AUTOSAR XML (schema 00052)
standard types defined: boolean, float64, sint8, uint16, uint32, uint8, boolean_CompuMethod, float64_DataConstr, sint8_DataConstr, uint16_DataConstr, uint32_DataConstr, uint8_DataConstr
package /ComponentTypes
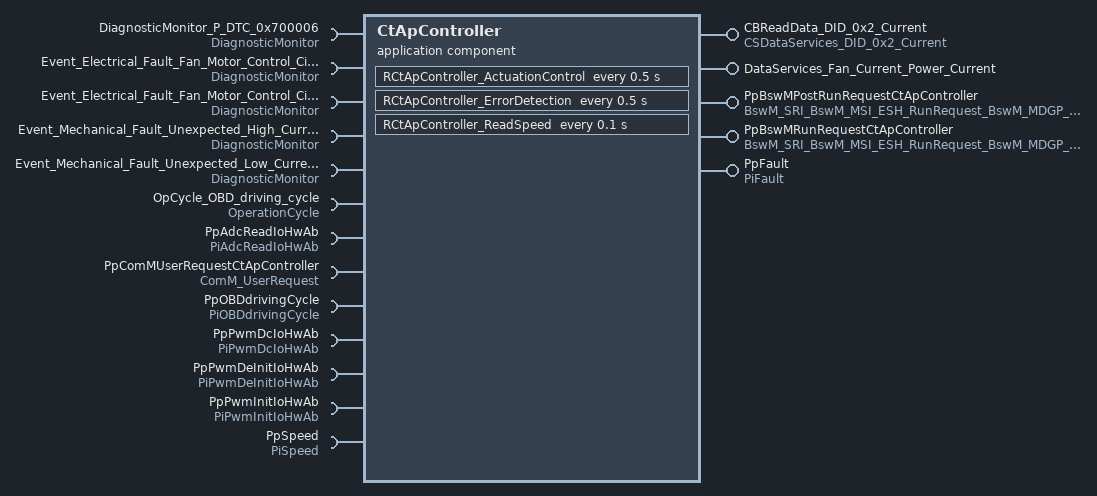
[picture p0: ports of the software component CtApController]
  application sw component type CtApController
    5 x provide port:
      CBReadData_DID_0x2_Current: server-com-spec{operation=CSDataServices_DID_0x2_Current/ReadData, queue-length=1}, provided-interface=CSDataServices_DID_0x2_Current
      DataServices_Fan_Current_Power_Current: provided-interface=DataServices_Fan_Current_Power_Current
        provided-com-specs:
          operation=ConditionCheckRead, queue-length=1
          operation=DataServices_Fan_Current_Power_Current/ReadData, queue-length=1
      PpBswMPostRunRequestCtApController: nonqueued-sender-com-spec=data-element=requestedMode, provided-interface=BswM_SRI_BswM_MSI_ESH_RunRequest_BswM_MDGP_ESH_RunRequest
      PpBswMRunRequestCtApController: nonqueued-sender-com-spec=data-element=requestedMode, provided-interface=BswM_SRI_BswM_MSI_ESH_RunRequest_BswM_MDGP_ESH_RunRequest
      PpFault: nonqueued-sender-com-spec{data-element=DeFault, init-value=0}, provided-interface=PiFault
    13 x require port:
      DiagnosticMonitor_P_DTC_0x700006: required-interface=DiagnosticMonitor
        required-com-specs:
          GetDTCOfEvent
          GetEventExtendedDataRecordEx
          GetEventFailed
          GetEventFreezeFrameDataEx
          GetEventStatus
          GetEventTested
          GetEventUdsStatus
          GetFaultDetectionCounter
          ResetEventDebounceStatus
          ResetEventStatus
          SetEventStatus
      Event_Electrical_Fault_Fan_Motor_Control_Circuit_Open: required-interface=DiagnosticMonitor
        required-com-specs:
          GetDTCOfEvent
          GetEventExtendedDataRecordEx
          GetEventFailed
          GetEventFreezeFrameDataEx
          GetEventStatus
          GetEventTested
          GetEventUdsStatus
          GetFaultDetectionCounter
          ResetEventDebounceStatus
          ResetEventStatus
          SetEventStatus
      Event_Electrical_Fault_Fan_Motor_Control_Circuit_Short: required-interface=DiagnosticMonitor
        required-com-specs:
          GetDTCOfEvent
          GetEventExtendedDataRecordEx
          GetEventFailed
          GetEventFreezeFrameDataEx
          GetEventStatus
          GetEventTested
          GetEventUdsStatus
          GetFaultDetectionCounter
          ResetEventDebounceStatus
          ResetEventStatus
          SetEventStatus
      Event_Mechanical_Fault_Unexpected_High_Current: required-interface=DiagnosticMonitor
        required-com-specs:
          GetDTCOfEvent
          GetEventExtendedDataRecordEx
          GetEventFailed
          GetEventFreezeFrameDataEx
          GetEventStatus
          GetEventTested
          GetEventUdsStatus
          GetFaultDetectionCounter
          ResetEventDebounceStatus
          ResetEventStatus
          SetEventStatus
      Event_Mechanical_Fault_Unexpected_Low_Current: required-interface=DiagnosticMonitor
        required-com-specs:
          GetDTCOfEvent
          GetEventExtendedDataRecordEx
          GetEventFailed
          GetEventFreezeFrameDataEx
          GetEventStatus
          GetEventTested
          GetEventUdsStatus
          GetFaultDetectionCounter
          ResetEventDebounceStatus
          ResetEventStatus
          SetEventStatus
      OpCycle_OBD_driving_cycle: required-com-specs=[GetOperationCycleState, SetOperationCycleState], required-interface=OperationCycle
      PpAdcReadIoHwAb: client-com-spec=ReadGroup, required-interface=PiAdcReadIoHwAb
      PpComMUserRequestCtApController: required-com-specs=[GetCurrentComMode, GetMaxComMode, GetRequestedComMode, RequestComMode], required-interface=ComM_UserRequest
      PpOBDdrivingCycle: nonqueued-receiver-com-spec{data-element=DeOBDdrivingCycle, filter=data-filter-type=ALWAYS, init-value=1}, required-interface=PiOBDdrivingCycle
      PpPwmDcIoHwAb: client-com-spec=SetDutyCycle, required-interface=PiPwmDcIoHwAb
      PpPwmDeInitIoHwAb: client-com-spec=Pwm_DeInit, required-interface=PiPwmDeInitIoHwAb
      PpPwmInitIoHwAb: client-com-spec=Pwm_Init, required-interface=PiPwmInitIoHwAb
      PpSpeed: nonqueued-receiver-com-spec{data-element=DeSpeed, alive-timeout=0.1, filter=data-filter-type=ALWAYS, init-value=0}, required-interface=PiSpeed
    behavior CtApController_InternalBehavior: handle-termination-and-restart=NO-SUPPORT
      exclusive area ExArFanCurrent
      ar-typed-per-instance-memorys:
        data PimFanCurrentDid: sw-calibration-access=READ-ONLY, type=uint8
      operation invoked event OIT_CBReadData_DID_0x2_Current_ReadData_CBReadData_DID_0x2_Current_ReadData: start-on-event=CBReadData_DID_0x2_Current_ReadData, operation=CBReadData_DID_0x2_Current.ReadData
      operation invoked event OIT_DataServices_Fan_Current_Power_Current_ConditionCheckRead_DataServices_Fan_Current_Power_Current_ConditionCheckRead: start-on-event=DataServices_Fan_Current_Power_Current_ConditionCheckRead, operation=DataServices_Fan_Current_Power_Current.ConditionCheckRead
      operation invoked event OIT_DataServices_Fan_Current_Power_Current_ReadData_DataServices_Fan_Current_Power_Current_ReadData: start-on-event=DataServices_Fan_Current_Power_Current_ReadData, operation=DataServices_Fan_Current_Power_Current.ReadData
      timing event TMT_ActuationControl: start-on-event=RCtApController_ActuationControl, period=0.5
      timing event TMT_CtApController_ErrorDetection: start-on-event=RCtApController_ErrorDetection, period=0.5
      init event CtApController_InitEvent: start-on-event=RCtApController_Init
      timing event TMT_RCtApController_ReadSpeed: start-on-event=RCtApController_ReadSpeed, period=0.1
      explicit-inter-runnable-variables:
        data IrvActuationControl: type=Idt_Speed_PWM_Struct, init-value=fields=[Speed:0, Pwm:0, RequestedSpeed:0]
        data IrvOBDdrivingCycleOld: type=boolean, init-value=1
        data IrvSpeed: type=Idt_Signal_Fan_Setpoint, init-value=0
      7 x runnable:
        CBReadData_DID_0x2_Current_ReadData
        DataServices_Fan_Current_Power_Current_ConditionCheckRead: can-enters=ExArFanCurrent
        DataServices_Fan_Current_Power_Current_ReadData: can-enters=ExArFanCurrent
        RCtApController_ActuationControl
          data-receive-point-by-arguments:
            access REC_PpMeasuredSpeed_DeSpeed: accessed-variable=PpSpeed.DeSpeed
            access REC_PpOBDdrivingCycle_DeOBDdrivingCycle: accessed-variable=PpOBDdrivingCycle.DeOBDdrivingCycle
          data-send-points:
            access SEND_PpHealth_DeHealth: accessed-variable=PpFault.DeFault
          read-local-variables:
            access Read_IrvOBDdrivingCycleOld: accessed-variable=IrvOBDdrivingCycleOld
            access Read_IrvSpeed: accessed-variable=IrvSpeed
          6 x sync call, all with timeout=0:
            SC_Event_Electrical_Fault_Fan_Motor_Control_Circuit_Open_GetEventUdsStatus: operation=Event_Electrical_Fault_Fan_Motor_Control_Circuit_Open.GetEventUdsStatus
            SC_Event_Electrical_Fault_Fan_Motor_Control_Circuit_Short_GetEventUdsStatus: operation=Event_Electrical_Fault_Fan_Motor_Control_Circuit_Short.GetEventUdsStatus
            SC_Event_Mechanical_Fault_Unexpected_High_Current_GetEventUdsStatus: operation=Event_Mechanical_Fault_Unexpected_High_Current.GetEventUdsStatus
            SC_Event_Mechanical_Fault_Unexpected_Low_Current_GetEventUdsStatus: operation=Event_Mechanical_Fault_Unexpected_Low_Current.GetEventUdsStatus
            SC_PpComMUserRequestCtApController_RequestComMode: operation=PpComMUserRequestCtApController.RequestComMode
            SC_PpPwmDcIoHwAb_SetDutyCycle: operation=PpPwmDcIoHwAb.SetDutyCycle
          written-local-variables:
            access WRITE_IrvOBDdrivingCycleOld: accessed-variable=IrvOBDdrivingCycleOld
            access WRITE_IrvActuationSpeed: accessed-variable=IrvActuationControl
        RCtApController_ErrorDetection
          data-send-points:
            access SEND_PpFault_DeFault: accessed-variable=PpFault.DeFault
          read-local-variables:
            access Read_IrvActuationSpeed: accessed-variable=IrvActuationControl
          6 x sync call, all with timeout=0:
            AC_PpAdcReadIoHwAb_ReadGroup: operation=PpAdcReadIoHwAb.ReadGroup
            SC_Event_Electrical_Fault_Fan_Motor_Control_Circuit_Open_SetEventStatus: operation=Event_Electrical_Fault_Fan_Motor_Control_Circuit_Open.SetEventStatus
            SC_Event_Electrical_Fault_Fan_Motor_Control_Circuit_Short_SetEventStatus: operation=Event_Electrical_Fault_Fan_Motor_Control_Circuit_Short.SetEventStatus
            SC_Event_Mechanical_Fault_Unexpected_High_Current_SetEventStatus: operation=Event_Mechanical_Fault_Unexpected_High_Current.SetEventStatus
            SC_Event_Mechanical_Fault_Unexpected_Low_Current_SetEventStatus: operation=Event_Mechanical_Fault_Unexpected_Low_Current.SetEventStatus
            SC_PpComMUserRequestCtApController_RequestComMode: operation=PpComMUserRequestCtApController.RequestComMode
        RCtApController_Init
          data-send-points:
            access SEND_PpBswMPostRunRequestCtApController_requestedMode: accessed-variable=PpBswMPostRunRequestCtApController.requestedMode
            access SEND_PpBswMRunRequestCtApController_requestedMode: accessed-variable=PpBswMRunRequestCtApController.requestedMode
          read-local-variables:
            access Read_IrvOBDdrivingCycleOld: accessed-variable=IrvOBDdrivingCycleOld
          sync call SC_OpCycle_OBD_driving_cycle_SetOperationCycleState: operation=OpCycle_OBD_driving_cycle.SetOperationCycleState, timeout=0
          sync call SC_PpComMUserRequestCtApController_RequestComMode: operation=PpComMUserRequestCtApController.RequestComMode, timeout=0
          written-local-variables:
            access WRITE_IrvOBDdrivingCycleOld: accessed-variable=IrvOBDdrivingCycleOld
        RCtApController_ReadSpeed
          data-receive-point-by-arguments:
            access REC_PpOBDdrivingCycle_DeOBDdrivingCycle: accessed-variable=PpOBDdrivingCycle.DeOBDdrivingCycle
            access REC_PpSpeed_DeSpeed: accessed-variable=PpSpeed.DeSpeed
          data-send-points:
            access SEND_PpFault_DeFault: accessed-variable=PpFault.DeFault
          read-local-variables:
            access Read_IrvOBDdrivingCycleOld: accessed-variable=IrvOBDdrivingCycleOld
          sync call SC_DiagnosticMonitor_P_DTC_0x700001_SetEventStatus: operation=DiagnosticMonitor_P_DTC_0x700006.SetEventStatus, timeout=0
          sync call SC_PpComMUserRequestCtApController_RequestComMode: operation=PpComMUserRequestCtApController.RequestComMode, timeout=0
          written-local-variables:
            access WRITE_IrvOBDdrivingCycleOld: accessed-variable=IrvOBDdrivingCycleOld
            access WRITE_IrvSpeed: accessed-variable=IrvSpeed
      swc service dependency SnNvMPimFanCurrentDid: category=SERVICE, assigned-datas=role-based-data-assignment={role=ramBlock, used-data-element=PimFanCurrentDid}
        service-needs:
          nv block needs SnNvMPimFanCurrentDid: n-data-sets=0, ram-block-status-control=API, readonly=false, reliability=NO-PROTECTION, resistant-to-changed-sw=false, restore-at-start=true, store-at-shutdown=true, write-only-once=false
      swc service dependency DiagnosticEventNeed_B_DTC_SPEEDOOR_0x700006: assigned-ports=role-based-port-assignment={port-prototype=DiagnosticMonitor_P_DTC_0x700006, role=DiagnosticMonitor}
        service-needs:
          diagnostic event needs DiagnosticEventNeed_B_DTC_SPEEDOOR_0x700006: uds-dtc-number=1
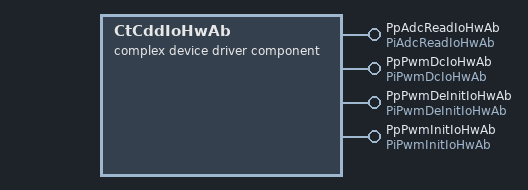
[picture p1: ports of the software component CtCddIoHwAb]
  complex device driver sw component type CtCddIoHwAb
    4 x provide port:
      PpAdcReadIoHwAb: server-com-spec{operation=ReadGroup, queue-length=1}, provided-interface=PiAdcReadIoHwAb
      PpPwmDcIoHwAb: server-com-spec{operation=SetDutyCycle, queue-length=1}, provided-interface=PiPwmDcIoHwAb
      PpPwmDeInitIoHwAb: server-com-spec{operation=Pwm_DeInit, queue-length=1}, provided-interface=PiPwmDeInitIoHwAb
      PpPwmInitIoHwAb: server-com-spec{operation=Pwm_Init, queue-length=1}, provided-interface=PiPwmInitIoHwAb
    behavior CtCddIoHwAb_InternalBehavior
      init event CtCddIoHwAb_InitEvent: start-on-event=RCtCddIoHwAb_Init
      4 x operation invoked event:
        OIT_RCtCddIoHwAb_PpAdcReadGroup_ReadGroup_PpAdcReadGroup_ReadGroup: start-on-event=RCtCddIoHwAb_PpAdcReadIoHwAb_ReadGroup, operation=PpAdcReadIoHwAb.ReadGroup
        OIT_RCtCddIoHwAb_PpPwmDcIoHwAb_SetDutyCycle_PpPwmDcIoHwAb_SetDutyCycle: start-on-event=RCtCddIoHwAb_PpPwmDcIoHwAb_SetDutyCycle, operation=PpPwmDcIoHwAb.SetDutyCycle
        OIT_RCtCddIoHwAb_PpPwmDeInitIoHwAb_Pwm_DeInit_PpPwmDeInitIoHwAb_Pwm_DeInit: start-on-event=RCtCddIoHwAb_PpPwmDeInitIoHwAb_Pwm_DeInit, operation=PpPwmDeInitIoHwAb.Pwm_DeInit
        OIT_RCtCddIoHwAb_PpPwmInitIoHwAb_Pwm_Init_PpPwmInitIoHwAb_Pwm_Init: start-on-event=RCtCddIoHwAb_PpPwmInitIoHwAb_Pwm_Init, operation=PpPwmInitIoHwAb.Pwm_Init
      5 x runnable:
        RCtCddIoHwAb_Init
        RCtCddIoHwAb_PpAdcReadIoHwAb_ReadGroup: can-be-invoked-concurrently=true
        RCtCddIoHwAb_PpPwmDcIoHwAb_SetDutyCycle
        RCtCddIoHwAb_PpPwmDeInitIoHwAb_Pwm_DeInit
        RCtCddIoHwAb_PpPwmInitIoHwAb_Pwm_Init
  swc implementation CtApController_Implementation: behavior=CtApController_InternalBehavior
    code-descriptors:
      code Default: artifact-descriptors=autosar-engineering-object={short-label=Default, category=SWSRC}
  swc implementation CtCddIoHwAb_Implementation: behavior=CtCddIoHwAb_InternalBehavior
    code-descriptors:
      code Default: artifact-descriptors=autosar-engineering-object={short-label=Default, category=SWSRC}
  ecu instance FanControlECU
package /DataTypes
  5 x impl type:
    Idt_Signal_Fan_Fault: category=VALUE, base-type=Temperature_BaseType, compu {1=Faulty, 0=NormalOperation}
    Idt_Signal_Fan_Setpoint: category=VALUE, base-type=Speed_BaseType, range raw 0..3500
    Idt_Speed_PWM_Struct: category=STRUCTURE, sw-calibration-access=READ-ONLY, type-emitter=RTE
      element Speed: range raw 0..3500, implementation-data-type=Idt_Signal_Fan_Setpoint
      element Pwm: range raw 0..32768, implementation-data-type=IdtPwmValueType
      element RequestedSpeed: range raw 0..3500, implementation-data-type=Idt_Signal_Fan_Setpoint
    IdtAdcResult: range raw >0..INF, implementation-data-type=float64, type-emitter=RTE
    IdtPwmValueType: range raw 0..32768, implementation-data-type=uint16, type-emitter=RTE
package /ECUCompositionTypes
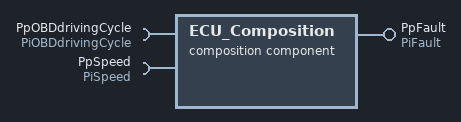
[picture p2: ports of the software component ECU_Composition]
  composition sw component type ECU_Composition
    provide port PpFault: nonqueued-sender-com-spec{data-element=DeFault, init-value=0}, provided-interface=PiFault
    require port PpOBDdrivingCycle: nonqueued-receiver-com-spec{data-element=DeOBDdrivingCycle, filter=data-filter-type=ALWAYS, init-value=1}, required-interface=PiOBDdrivingCycle
    require port PpSpeed: nonqueued-receiver-com-spec{data-element=DeSpeed, filter=data-filter-type=ALWAYS, init-value=0}, required-interface=PiSpeed
    component CpApController: type=CtApController
    component CpCddIoHwAb: type=CtCddIoHwAb
    connect CpCddIoHwAb.PpAdcReadIoHwAb -> CpApController.PpAdcReadIoHwAb
    connect CpCddIoHwAb.PpPwmDcIoHwAb -> CpApController.PpPwmDcIoHwAb
    connect CpCddIoHwAb.PpPwmDeInitIoHwAb -> CpApController.PpPwmDeInitIoHwAb
    connect CpCddIoHwAb.PpPwmInitIoHwAb -> CpApController.PpPwmInitIoHwAb
    delegate CpApController.PpFault <-> outer port ECU_Composition/PpFault
    delegate CpApController.PpOBDdrivingCycle <-> outer port ECU_Composition/PpOBDdrivingCycle
    delegate CpApController.PpSpeed <-> outer port ECU_Composition/PpSpeed
package /MICROSAR_Imported/BswM_swc/DataTypes
  impl type BswM_ESH_RunRequest: compu {0=RELEASED, 1=REQUESTED}, range raw 0..255, implementation-data-type=uint8  # Unique value for each user
package /MICROSAR_Imported/BswM_swc/Interfaces
  sender receiver interface BswM_SRI_BswM_MSI_ESH_RunRequest_BswM_MDGP_ESH_RunRequest: is-service=true, service-kind=BASIC-SOFTWARE-MODE-MANAGER, invalidation-policy{data-element=requestedMode, handle-invalid=DONT-INVALIDATE}
    data requestedMode: type=BswM_ESH_RunRequest
package /MICROSAR_Imported/ComM_swc/DataTypes
  impl type ComM_ModeType: compu {0=COMM_NO_COMMUNICATION, 1=COMM_SILENT_COMMUNICATION, 2=COMM_FULL_COMMUNICATION}, range raw 0..3, implementation-data-type=uint8
package /MICROSAR_Imported/ComM_swc/Interfaces
  client server interface ComM_UserRequest: is-service=true, service-kind=COM-MANAGER
    4 x operation:
      GetCurrentComMode: possible-error=ComM_UserRequest/E_NOT_OK
        arg ComMode: type=ComM_ModeType, direction=OUT, server-argument-impl-policy=USE-ARGUMENT-TYPE
      GetMaxComMode: possible-error=ComM_UserRequest/E_NOT_OK
        arg ComMode: type=ComM_ModeType, direction=OUT, server-argument-impl-policy=USE-ARGUMENT-TYPE
      GetRequestedComMode: possible-error=ComM_UserRequest/E_NOT_OK
        arg ComMode: type=ComM_ModeType, direction=OUT, server-argument-impl-policy=USE-ARGUMENT-TYPE
      RequestComMode: possible-error=[E_MODE_LIMITATION, ComM_UserRequest/E_NOT_OK]
        arg ComMode: type=ComM_ModeType, direction=IN, server-argument-impl-policy=USE-ARGUMENT-TYPE
    4 x error:
      E_MODE_LIMITATION: error-code=2
      E_MULTIPLE_PNC_ASSIGNED: error-code=3
      E_NO_PNC_ASSIGNED: error-code=4
      E_NOT_OK: error-code=1
package /MICROSAR_Imported/Dcm_swc/DataTypes
  impl type Dcm_Data1ByteType: category=ARRAY, sw-calibration-access=READ-ONLY
    element Dcm_Data1ByteTypeElement: array-size=1, array-size-semantics=FIXED-SIZE, implementation-data-type=uint8
  impl type Dcm_NegativeResponseCodeType:
    compu {0=DCM_E_POSITIVERESPONSE, 16=DCM_E_GENERALREJECT, 17=DCM_E_SERVICENOTSUPPORTED, 18=DCM_E_SUBFUNCTIONNOTSUPPORTED, 19=DCM_E_INCORRECTMESSAGELENGTHORINVALIDFORMAT, 20=DCM_E_RESPONSETOOLONG, 33=DCM_E_BUSYREPEATREQUEST, 34=DCM_E_CONDITIONSNOTCORRECT, 36=DCM_E_REQUESTSEQUENCEERROR, 37=DCM_E_NORESPONSEFROMSUBNETCOMPONENT, 38=DCM_E_FAILUREPREVENTSEXECUTIONOFREQUESTEDACTION, 49=DCM_E_REQUESTOUTOFRANGE, 51=DCM_E_SECURITYACCESSDENIED, 52=DCM_E_AUTHENTICATIONREQUIRED, 53=DCM_E_INVALIDKEY, 54=DCM_E_EXCEEDNUMBEROFATTEMPTS, 55=DCM_E_REQUIREDTIMEDELAYNOTEXPIRED, 80=DCM_E_CVF_INVALIDTIMEPERIOD, 81=DCM_E_CVF_INVALIDSIGNATURE, 82=DCM_E_CVF_INVALIDCHAINOFTRUST, 83=DCM_E_CVF_INVALIDTYPE, 84=DCM_E_CVF_INVALIDFORMAT, 85=DCM_E_CVF_INVALIDCONTENT, 86=DCM_E_CVF_INVALIDSCOPE, 87=DCM_E_CVF_INVALIDCERTIFICATEREVOKED, 88=DCM_E_OWNERSHIPVERIFICATIONFAILED, 89=DCM_E_CHALLENGECALCULATIONFAILED, 112=DCM_E_UPLOADDOWNLOADNOTACCEPTED, 113=DCM_E_TRANSFERDATASUSPENDED, 114=DCM_E_GENERALPROGRAMMINGFAILURE, 115=DCM_E_WRONGBLOCKSEQUENCECOUNTER, 120=DCM_E_REQUESTCORRECTLYRECEIVEDRESPONSEPENDING, 126=DCM_E_SUBFUNCTIONNOTSUPPORTEDINACTIVESESSION, 127=DCM_E_SERVICENOTSUPPORTEDINACTIVESESSION, 129=DCM_E_RPMTOOHIGH, 130=DCM_E_RPMTOOLOW, 131=DCM_E_ENGINEISRUNNING, 132=DCM_E_ENGINEISNOTRUNNING, 133=DCM_E_ENGINERUNTIMETOOLOW, 134=DCM_E_TEMPERATURETOOHIGH, 135=DCM_E_TEMPERATURETOOLOW, 136=DCM_E_VEHICLESPEEDTOOHIGH, 137=DCM_E_VEHICLESPEEDTOOLOW, 138=DCM_E_THROTTLE_PEDALTOOHIGH, 139=DCM_E_THROTTLE_PEDALTOOLOW, 140=DCM_E_TRANSMISSIONRANGENOTINNEUTRAL, 141=DCM_E_TRANSMISSIONRANGENOTINGEAR, 143=DCM_E_BRAKESWITCH_NOTCLOSED, 144=DCM_E_SHIFTERLEVERNOTINPARK, 145=DCM_E_TORQUECONVERTERCLUTCHLOCKED, 146=DCM_E_VOLTAGETOOHIGH, 147=DCM_E_VOLTAGETOOLOW, 240..249=DCM_E_VMSCNC_0..DCM_E_VMSCNC_9, 250=DCM_E_VMSCNC_A, 251=DCM_E_VMSCNC_B, 252=DCM_E_VMSCNC_C, 253=DCM_E_VMSCNC_D, 254=DCM_E_VMSCNC_E}
    range raw 0..255
    implementation-data-type=uint8
  impl type Dcm_OpStatusType: compu {0=DCM_INITIAL, 1=DCM_PENDING, 2=DCM_CANCEL, 3=DCM_FORCE_RCRRP_OK, 64=DCM_FORCE_RCRRP_NOT_OK}, range raw 0..64, implementation-data-type=uint8
package /MICROSAR_Imported/Dcm_swc/Interfaces
  client server interface DataServices_Fan_Current_Power_Current: is-service=true, service-kind=DIAGNOSTIC-COMMUNICATION-MANAGER
    operation ConditionCheckRead: possible-error=[DCM_E_PENDING, DataServices_Fan_Current_Power_Current/E_NOT_OK]
      arg OpStatus: type=Dcm_OpStatusType, direction=IN, server-argument-impl-policy=USE-ARGUMENT-TYPE
      arg ErrorCode: type=Dcm_NegativeResponseCodeType, direction=OUT, server-argument-impl-policy=USE-ARGUMENT-TYPE
    operation ReadData: possible-error=[DCM_E_PENDING, DataServices_Fan_Current_Power_Current/E_NOT_OK]
      arg OpStatus: type=Dcm_OpStatusType, direction=IN, server-argument-impl-policy=USE-ARGUMENT-TYPE
      arg Data: type=Dcm_Data1ByteType, direction=OUT, server-argument-impl-policy=USE-ARGUMENT-TYPE
    error DCM_E_PENDING: error-code=10
    error E_NOT_OK: error-code=1
package /MICROSAR_Imported/Dem_swc/DataTypes
  7 x impl type:
    DataPrimitiveType_uint8: implementation-data-type=uint8
    Dem_DebounceResetStatusType: compu {0=DEM_DEBOUNCE_STATUS_FREEZE, 1=DEM_DEBOUNCE_STATUS_RESET}, range raw 0..255, implementation-data-type=uint8
    Dem_DTCFormatType: compu {0=DEM_DTC_FORMAT_OBD, 1=DEM_DTC_FORMAT_UDS, 2=DEM_DTC_FORMAT_J1939}, range raw 0..2, implementation-data-type=uint8
    Dem_EventStatusType:
      compu {0=DEM_EVENT_STATUS_PASSED, 1=DEM_EVENT_STATUS_FAILED, 2=DEM_EVENT_STATUS_PREPASSED, 3=DEM_EVENT_STATUS_PREFAILED, 4=DEM_EVENT_STATUS_FDC_THRESHOLD_REACHED, 5=DEM_EVENT_STATUS_PASSED_CONDITIONS_NOT_FULFILLED, 6=DEM_EVENT_STATUS_FAILED_CONDITIONS_NOT_FULFILLED, 7=DEM_EVENT_STATUS_PREPASSED_CONDITIONS_NOT_FULFILLED, 8=DEM_EVENT_STATUS_PREFAILED_CONDITIONS_NOT_FULFILLED}
      range raw 0..255
      implementation-data-type=uint8
    Dem_MaxDataValueType: category=ARRAY, sw-calibration-access=READ-ONLY
      element Dem_MaxDataValueTypeElement: array-size=1, array-size-semantics=FIXED-SIZE, implementation-data-type=uint8
    Dem_OperationCycleStateType: compu {0=DEM_CYCLE_STATE_START, 1=DEM_CYCLE_STATE_END}, range raw 0..1, implementation-data-type=uint8
    Dem_UdsStatusByteType:
      compu {mask 1: 1=DEM_UDS_STATUS_TF (bit 0: TestFailed), mask 2: 2=DEM_UDS_STATUS_TFTOC (bit 1: TestFailedThisOperationCycle), mask 4: 4=DEM_UDS_STATUS_PDTC (bit 2: PendingDTC), mask 8: 8=DEM_UDS_STATUS_CDTC (bit 3: ConfirmedDTC), mask 16: 16=DEM_UDS_STATUS_TNCSLC (bit 4: TestNotCompletedSinceLastClear), mask 32: 32=DEM_UDS_STATUS_TFSLC (bit 5: TestFailedSinceLastClear), mask 64: 64=DEM_UDS_STATUS_TNCTOC (bit 6: TestNotCompletedThisOperationCycle), mask 128: 128=DEM_UDS_STATUS_WIR (bit 7: WarningIndicatorRequested)}
      range raw 0..255
      implementation-data-type=uint8
package /MICROSAR_Imported/Dem_swc/Interfaces
  client server interface CSDataServices_DID_0x2_Current: is-service=true, service-kind=DIAGNOSTIC-EVENT-MANAGER
    operation ReadData: possible-error=CSDataServices_DID_0x2_Current/E_NOT_OK
      arg Data: type=DataPrimitiveType_uint8, direction=OUT, server-argument-impl-policy=USE-ARGUMENT-TYPE
    error E_NOT_OK: error-code=1
  client server interface DiagnosticMonitor: is-service=true, service-kind=DIAGNOSTIC-EVENT-MANAGER
    11 x operation:
      GetDTCOfEvent: possible-error=[DEM_E_NO_DTC_AVAILABLE, DiagnosticMonitor/E_NOT_OK]
        arg DTCFormat: type=Dem_DTCFormatType, direction=IN, server-argument-impl-policy=USE-ARGUMENT-TYPE
        arg DTCOfEvent: type=uint32, direction=OUT, server-argument-impl-policy=USE-ARGUMENT-TYPE
      GetEventExtendedDataRecordEx: possible-error=[DEM_BUFFER_TOO_SMALL, DEM_NO_SUCH_ELEMENT, DiagnosticMonitor/E_NOT_OK]
        arg RecordNumber: type=uint8, direction=IN, server-argument-impl-policy=USE-ARGUMENT-TYPE
        arg DestBuffer: type=Dem_MaxDataValueType, direction=OUT, server-argument-impl-policy=USE-ARGUMENT-TYPE
        arg BufSize: type=uint16, direction=INOUT, server-argument-impl-policy=USE-ARGUMENT-TYPE
      GetEventFailed: possible-error=DiagnosticMonitor/E_NOT_OK
        arg EventFailed: type=boolean, direction=OUT, server-argument-impl-policy=USE-ARGUMENT-TYPE
      GetEventFreezeFrameDataEx: possible-error=[DEM_BUFFER_TOO_SMALL, DEM_NO_SUCH_ELEMENT, DiagnosticMonitor/E_NOT_OK]
        4 x arg, all with server-argument-impl-policy=USE-ARGUMENT-TYPE:
          RecordNumber: type=uint8, direction=IN
          DataId: type=uint16, direction=IN
          DestBuffer: type=Dem_MaxDataValueType, direction=OUT
          BufSize: type=uint16, direction=INOUT
      GetEventStatus: possible-error=DiagnosticMonitor/E_NOT_OK
        arg UDSStatusByte: type=Dem_UdsStatusByteType, direction=OUT, server-argument-impl-policy=USE-ARGUMENT-TYPE
      GetEventTested: possible-error=DiagnosticMonitor/E_NOT_OK
        arg EventTested: type=boolean, direction=OUT, server-argument-impl-policy=USE-ARGUMENT-TYPE
      GetEventUdsStatus: possible-error=DiagnosticMonitor/E_NOT_OK
        arg UDSStatusByte: type=Dem_UdsStatusByteType, direction=OUT, server-argument-impl-policy=USE-ARGUMENT-TYPE
      GetFaultDetectionCounter: possible-error=[DEM_E_NO_FDC_AVAILABLE, DiagnosticMonitor/E_NOT_OK]
        arg FaultDetectionCounter: type=sint8, direction=OUT, server-argument-impl-policy=USE-ARGUMENT-TYPE
      ResetEventDebounceStatus: possible-error=DiagnosticMonitor/E_NOT_OK
        arg DebounceResetStatus: type=Dem_DebounceResetStatusType, direction=IN, server-argument-impl-policy=USE-ARGUMENT-TYPE
      ResetEventStatus: possible-error=DiagnosticMonitor/E_NOT_OK
      SetEventStatus: possible-error=DiagnosticMonitor/E_NOT_OK
        arg EventStatus: type=Dem_EventStatusType, direction=IN, server-argument-impl-policy=USE-ARGUMENT-TYPE
    5 x error:
      DEM_BUFFER_TOO_SMALL: error-code=21
      DEM_E_NO_DTC_AVAILABLE: error-code=10
      DEM_E_NO_FDC_AVAILABLE: error-code=14
      DEM_NO_SUCH_ELEMENT: error-code=48
      E_NOT_OK: error-code=1
  client server interface OperationCycle: is-service=true, service-kind=DIAGNOSTIC-EVENT-MANAGER
    operation GetOperationCycleState: possible-error=[OperationCycle/E_NOT_OK, E_OK]
      arg CycleState: type=Dem_OperationCycleStateType, direction=OUT, server-argument-impl-policy=USE-ARGUMENT-TYPE
    operation SetOperationCycleState: possible-error=[OperationCycle/E_NOT_OK, E_OK]
      arg CycleState: type=Dem_OperationCycleStateType, direction=IN, server-argument-impl-policy=USE-ARGUMENT-TYPE
    error E_NOT_OK: error-code=1
    error E_OK: error-code=0
package /PortInterfaces
  4 x client server interface:
    PiAdcReadIoHwAb
      operation ReadGroup
        arg adcResult: type=IdtAdcResult, direction=OUT, server-argument-impl-policy=USE-ARGUMENT-TYPE
      error E_NOT_OK: error-code=1
    PiPwmDcIoHwAb
      operation SetDutyCycle
        arg value: type=IdtPwmValueType, direction=OUT, server-argument-impl-policy=USE-ARGUMENT-TYPE
    PiPwmDeInitIoHwAb
      operation Pwm_DeInit
    PiPwmInitIoHwAb
      operation Pwm_Init
  sender receiver interface PiFault: invalidation-policy{data-element=DeFault, handle-invalid=DONT-INVALIDATE}
    data DeFault: range raw 0..1, type=Idt_Signal_Fan_Fault
  sender receiver interface PiOBDdrivingCycle: invalidation-policy{data-element=DeOBDdrivingCycle, handle-invalid=DONT-INVALIDATE}
    data DeOBDdrivingCycle: range raw 0..1, type=uint8
  sender receiver interface PiSpeed: invalidation-policy{data-element=DeSpeed, handle-invalid=DONT-INVALIDATE}
    data DeSpeed: range raw 0..3500, type=Idt_Signal_Fan_Setpoint
package /VectorAutosarExplorerGeneratedObjects/BASE_TYPES
  base type Speed_BaseType: category=FIXED_LENGTH, base-type-size=16, base-type-encoding=NONE, native-declaration=uint16
  base type Temperature_BaseType: category=FIXED_LENGTH, base-type-size=16, base-type-encoding=2C, native-declaration=uint8
package /Systems
  system FanControlECU
    system mapping Mapping
      sw-mappings:
        swc to ecu mapping SwcToFanControlECUMapping: component=[ECU_Composition.CpApController, ECU_Composition.CpCddIoHwAb], ecu-instance=FanControlECU
    root-software-compositions:
      root sw composition prototype ECU_Composition: software-composition=ECU_Composition
